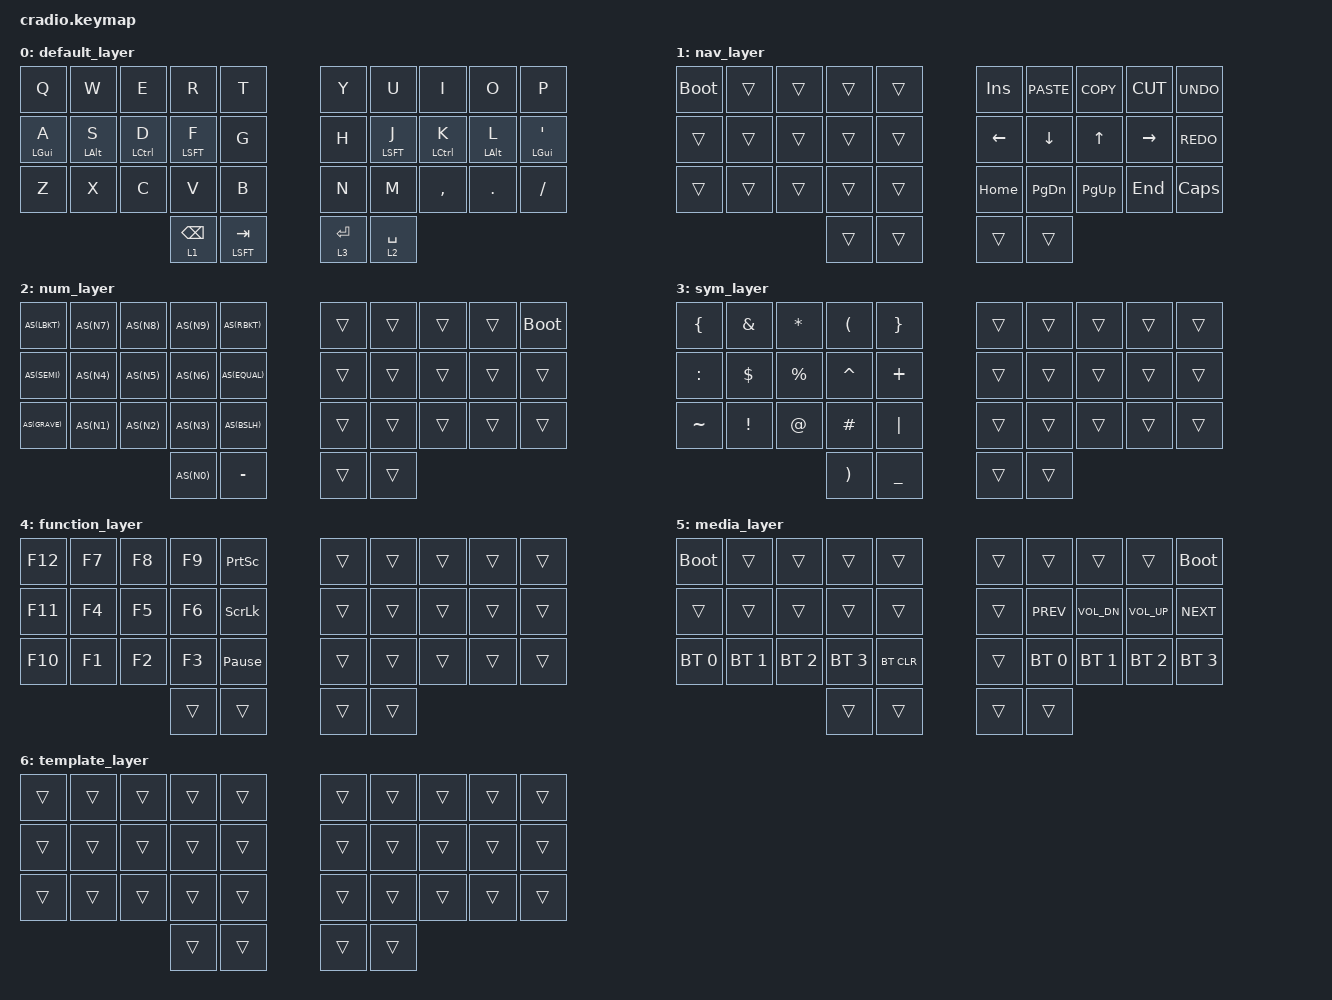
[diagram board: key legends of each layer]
// -*- mode: c; c-basic-offset: 2; indent-tabs-mode: nil -*-

// Copyright (c) 2022 The ZMK Contributors
// SPDX-License-Identifier: MIT

#include <behaviors.dtsi>
#include <dt-bindings/zmk/keys.h>
#include <dt-bindings/zmk/bt.h>

// Home row mods - Left
#define _A &homey_left LGUI A
#define _S &homey_left LALT S
#define _D &homey_left LCTL D
#define _F &homey_left LSFT F

// Home row mods - Right
#define _J    &homey_right LSFT J	
#define _K    &homey_right LCTL K
#define _L    &homey_right LALT L
#define _SEMI &homey_right LGUI SEMI
#define _QUOT &homey_right LGUI QUOT

// Left thumbs
#define NAV_BS  &lt 1 BSPC
#define MOS_TAB &lt 5 TAB
#define MED_ESC &lt 6 ESC
#define SFT_TAB &mt LSFT TAB

// Right thumbs
#define NUM_SPC &lt 2 SPACE
#define SYM_ENT &lt 3 ENTER
//#define SYM_ENT &mt LGUI ENTER
#define FUN_DEL &lt 4 DEL

// Shorter media codes.
#define _VOL_UP &kp  C_VOL_UP
#define _VOL_DN &kp  C_VOL_DN
#define _M_NEXT &kp  C_NEXT
#define _M_PREV &kp  C_PREV

// Shorter bluetooth codes.
#define BT0         &bt BT_SEL 0
#define BT1         &bt BT_SEL 1
#define BT2         &bt BT_SEL 2
#define BT3         &bt BT_SEL 3
#define BT4         &bt BT_SEL 4
#define _BT_CLR     &bt BT_CLR

#define BOOT   &bootloader
#define _PAUSE &kp PAUSE_BREAK

/ {

  behaviors {
    
    // Home row mod configuration from
    //     https://github.com/sunaku/glove80-keymaps
#define TYPING_STREAK_TERM 160 // global-quick-tap-ms
#define KEY_REPEATING_TERM 300 // "tap then hold" for key auto-repeat
#define HOMEY_TAPPING_TERM 260 // TAPPING_TERM + ALLOW_CROSSOVER_AFTER
#define HOMEY_HOLDING_TYPE "tap-preferred"
#define INDEX_TAPPING_TERM 180
#define INDEX_HOLDING_TYPE "tap-preferred"
#define LEFT_HAND_KEYS				\
      0 1 2 3 4					\
      10 11 12 13 14				\
      20 21 22 23 24				\
      32 33 34 35
#define RIGHT_HAND_KEYS				\
      5 6 7 8 9					\
      15 16 17 18 19				\
      27 28 29 30 31				\
      36 37 38 39
    homey_left: miryoku_home_row_mods_left_hand {
      compatible = "zmk,behavior-hold-tap";
      label = "HOME_ROW_MODS_LEFT_HAND";
      flavor = HOMEY_HOLDING_TYPE;
      hold-trigger-key-positions = <RIGHT_HAND_KEYS>;
      hold-trigger-on-release; // wait for other home row mods
      tapping-term-ms = <HOMEY_TAPPING_TERM>;
      quick-tap-ms = <TYPING_STREAK_TERM>;
      global-quick-tap; // with typing streak
      #binding-cells = <2>;
      bindings = <&kp>, <&kp>;
    };
    homey_right: miryoku_home_row_mods_right_hand {
      compatible = "zmk,behavior-hold-tap";
      label = "HOME_ROW_MODS_RIGHT_HAND";
      flavor = HOMEY_HOLDING_TYPE;
      hold-trigger-key-positions = <LEFT_HAND_KEYS>;
      hold-trigger-on-release; // wait for other home row mods
      tapping-term-ms = <HOMEY_TAPPING_TERM>;
      quick-tap-ms = <TYPING_STREAK_TERM>;
      global-quick-tap; // with typing streak
      #binding-cells = <2>;
      bindings = <&kp>, <&kp>;
    };
    index_left: miryoku_home_row_mods_left_index_shift {
      compatible = "zmk,behavior-hold-tap";
      label = "HOME_ROW_MODS_LEFT_INDEX_SHIFT";
      flavor = INDEX_HOLDING_TYPE;
      hold-trigger-key-positions = <RIGHT_HAND_KEYS>;
      //hold-trigger-on-release; // don't wait for other mods
      tapping-term-ms = <INDEX_TAPPING_TERM>;
      quick-tap-ms = <KEY_REPEATING_TERM>; // enable repeat
      //global-quick-tap; // no typing streak
      #binding-cells = <2>;
      bindings = <&kp>, <&kp>;
    };
    index_right: miryoku_home_row_mods_right_index_shift {
      compatible = "zmk,behavior-hold-tap";
      label = "HOME_ROW_MODS_RIGHT_INDEX_SHIFT";
      flavor = INDEX_HOLDING_TYPE;
      hold-trigger-key-positions = <LEFT_HAND_KEYS>;
      //hold-trigger-on-release; // don't wait for other mods
      tapping-term-ms = <INDEX_TAPPING_TERM>;
      quick-tap-ms = <KEY_REPEATING_TERM>; // enable repeat
      //global-quick-tap; // no typing streak
      #binding-cells = <2>;
      bindings = <&kp>, <&kp>;
    };
      
    // Autoshift.
    as: auto_shift {
      compatible = "zmk,behavior-hold-tap";
      label = "AUTO_SHIFT";
      #binding-cells = <2>;
      tapping_term_ms = <135>;
      quick_tap_ms = <0>;
      flavor = "tap-preferred";
      bindings = <&kp>, <&kp>;
    };
    #define AS(keycode) &as LS(keycode) keycode

  };

  keymap {
    compatible = "zmk,keymap";
    default_layer {
      bindings = <
	&kp Q  &kp W   &kp E   &kp R   &kp T            /**/           &kp Y   &kp U   &kp I      &kp O    &kp P
	_A     _S      _D      _F      &kp G            /**/           &kp H   _J      _K         _L       _QUOT
	&kp Z  &kp X   &kp C   &kp V   &kp B            /**/           &kp N   &kp M   &kp COMMA  &kp DOT  &kp FSLH
                                       NAV_BS  SFT_TAB  /**/  SYM_ENT  NUM_SPC                        
	>;
    };

    // Layer 1
    // Nav Layer
    // Miryoku like:
    // - vi style nav
    // - insert moved off pinky (which is there due to the vi stle
    //   nav), shuffling the other keys like paste, copy, etc.
    nav_layer {
      bindings = <
	BOOT       &trans     &trans     &trans     &trans             /**/              &kp INS    &kp K_PASTE &kp K_COPY  &kp K_CUT  &kp K_UNDO
	&trans     &trans     &trans     &trans     &trans             /**/              &kp LEFT   &kp DOWN    &kp UP      &kp RIGHT  &kp K_REDO
	&trans     &trans     &trans     &trans     &trans             /**/              &kp HOME   &kp PG_DN   &kp PG_UP   &kp END    &kp CAPS
	                                            &trans     &trans  /**/   &trans     &trans                       
	>;
    };

    // Layer 2
    // - Num layer
    // - Miryoku
    num_layer {
      bindings = <
	AS(LBKT)   AS(N7)     AS(N8)     AS(N9)     AS(RBKT)            /**/              &trans     &trans     &trans     &trans     BOOT
	AS(SEMI)   AS(N4)     AS(N5)     AS(N6)     AS(EQUAL)           /**/              &trans     &trans     &trans     &trans     &trans
	AS(GRAVE)  AS(N1)     AS(N2)     AS(N3)     AS(BSLH)            /**/              &trans     &trans     &trans     &trans     &trans
	                                            AS(N0)    &kp MINUS /**/   &trans     &trans                        
	>;
    };

    // Layer 3
    // - Sym layer
    // - Miryoku
    sym_layer {
      bindings = <
	&kp LBRC   &kp AMPS   &kp STAR   &kp LPAR   &kp RBRC             /**/              &trans     &trans     &trans     &trans     &trans
	&kp COLON  &kp DLLR   &kp PRCNT  &kp CARET  &kp PLUS             /**/              &trans     &trans     &trans     &trans     &trans
	&kp TILDE  &kp EXCL   &kp AT     &kp HASH   &kp PIPE             /**/              &trans     &trans     &trans     &trans     &trans
                                                    &kp RPAR   &kp UNDER /**/   &trans     &trans                       
	>;
    };

    // Layer 4
    // - Function layer
    // - Miryoku
    function_layer {
      bindings = <
        &kp F12    &kp F7     &kp F8     &kp F9     &kp PSCRN          /**/              &trans     &trans     &trans     &trans     &trans
        &kp F11    &kp F4     &kp F5     &kp F6     &kp SLCK           /**/              &trans     &trans     &trans     &trans     &trans
        &kp F10    &kp F1     &kp F2     &kp F3     _PAUSE             /**/              &trans     &trans     &trans     &trans     &trans
                                                    &trans     &trans  /**/   &trans     &trans                      
	>;
    };

#if 0
    // Layer 5
    mouse_layer {
      bindings = <
        &trans     &trans     &trans     &trans     &trans             /**/              &trans     &trans     &trans     &trans     &trans
        &trans     &trans     &trans     &trans     &trans             /**/              _MSL       _MSD       _MSU       _MSR       &trans
        &trans     &trans     &trans     &trans     &trans             /**/              _MWL       _MWD       _MWU       _MWR       &trans
                                                    &trans     &trans  /**/   _MBR       _MBL                          
        >;
    };
#endif

    // Layer 6
    // - Media layer
    // - Miryoku, no power toggle or rgb though.
    media_layer {
      bindings = <
	BOOT       &trans     &trans     &trans     &trans             /**/              &trans     &trans     &trans     &trans     BOOT
	&trans     &trans     &trans     &trans     &trans             /**/              &trans     _M_PREV    _VOL_DN    _VOL_UP    _M_NEXT
	BT0        BT1        BT2        BT3        _BT_CLR            /**/              &trans     BT0        BT1        BT2        BT3   
                                                    &trans     &trans  /**/   &trans     &trans                       
	>;
	
      sensor-bindings = <&inc_dec_kp C_VOL_DN C_VOL_UP>;
    };

    template_layer {
      bindings = <
        &trans     &trans     &trans     &trans     &trans  /**/       &trans     &trans     &trans     &trans     &trans
        &trans     &trans     &trans     &trans     &trans  /**/       &trans     &trans     &trans     &trans     &trans
        &trans     &trans     &trans     &trans     &trans  /**/       &trans     &trans     &trans     &trans     &trans
                                         &trans     &trans  /**/       &trans     &trans
        >;
    };

  };
};
